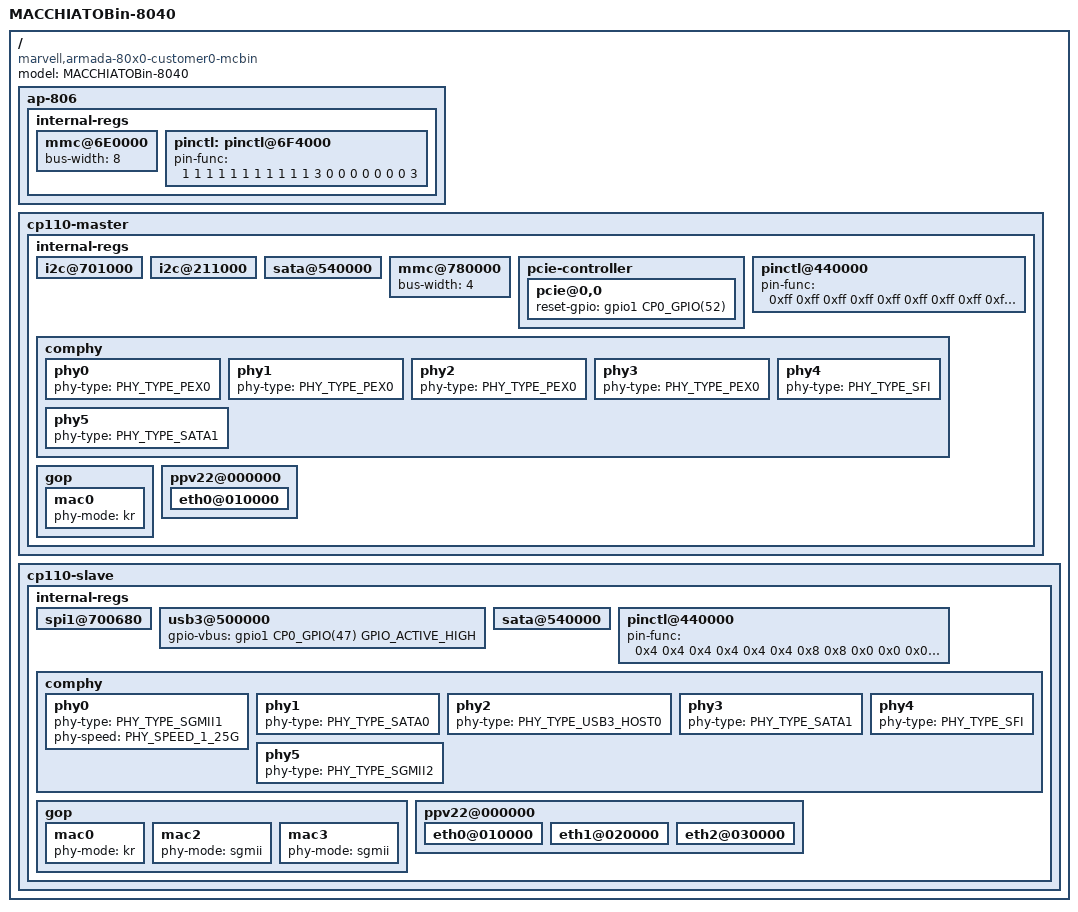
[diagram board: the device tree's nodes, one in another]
/*
 * ***************************************************************************
 * Copyright (C) 2016 Marvell International Ltd.
 * ***************************************************************************
 * This program is free software: you can redistribute it and/or modify it
 * under the terms of the GNU General Public License as published by the Free
 * Software Foundation, either version 2 of the License, or any later version.
 *
 * This program is distributed in the hope that it will be useful,
 * but WITHOUT ANY WARRANTY; without even the implied warranty of
 * MERCHANTABILITY or FITNESS FOR A PARTICULAR PURPOSE.  See the
 * GNU General Public License for more details.
 *
 * You should have received a copy of the GNU General Public License
 * along with this program.  If not, see <http://www.gnu.org/licenses/>.
 * ***************************************************************************
 */

/dts-v1/;

#include "armada-80x0.dtsi" /* include SoC device tree */

/ {
	model = "MACCHIATOBin-8040";
	compatible = "marvell,armada-80x0-customer0-mcbin", "marvell,armada-80x0";

	ap-806 {
		internal-regs {
			mmc@6E0000 {
				/* on-board eMMC */
				bus-width= <8>;
				status = "okay";
			};
			pinctl: pinctl@6F4000 {
					/* MPP Bus:
						eMMC [0..10]
						UART0 [11,19]
					*/
					  /* 0 1 2 3 4 5 6 7 8 9 */
				pin-func = < 1 1 1 1 1 1 1 1 1 1
					     1 3 0 0 0 0 0 0 0 3>;
			};
		};
	};
	cp110-master {
		internal-regs {
			i2c@701000 {
				status = "okay";
			};
			i2c@211000 {
				status = "okay";
			};
			sata@540000 {
				status = "okay";
			};
			mmc@780000 {
				/* uSD slot */
				bus-width= <4>;
				status = "okay";
			};
			pcie-controller {
				pcie@0,0 {
					reset-gpio = <&gpio1 CP0_GPIO(52) GPIO_ACTIVE_HIGH>;
					status = "okay";
				};
			};
			pinctl@440000 {
					/* MPP Bus:
					   [0-31] = 0xff: Keep default CP0_shared_pins:
						[11] CLKOUT_MPP_11 (out)
						[23] LINK_RD_IN_CP2CP (in)
						[25] CLKOUT_MPP_25 (out)
						[29] AVS_FB_IN_CP2CP (in)
					   [32,34] SMI
					   [33]    MSS power down
					   [35..38] CP0 I2C1 and I2C0
					   [39] MSS CKE Enable
					   [40,41] CP0 UART1 TX/RX
					   [42,43] XSMI (controls two 10G phys)
					   [47] USB VBUS EN
					   [48] FAN PWM
					   [49] 10G port 1 interrupt
					   [50] 10G port 0 interrupt
					   [51] 2.5G SFP TX fault
					   [52] PCIe reset out
					   [53] 2.5G SFP mode
					   [54] 2.5G SFP LOS
					   [55] Micro SD card detect
					   [56-61] Micro SD
					   [62] CP1 SFI SFP FAULT
					*/
					/*   0    1    2    3    4    5    6    7    8    9 */
				pin-func = < 0xff 0xff 0xff 0xff 0xff 0xff 0xff 0xff 0xff 0xff
					     0xff 0xff 0xff 0xff 0xff 0xff 0xff 0xff 0xff 0xff
					     0xff 0xff 0xff 0xff 0xff 0xff 0xff 0xff 0xff 0xff
					     0xff 0    7    0xa  7    2    2    2    2    0xa
					     7    7    8    8    0    0    0    0    0    0
					     0    0    9    0    0    0    0xe  0xe  0xe  0xe
					     0xe  0xe  0>;
			};

			comphy {
				/* CP0 Serdes Configuration:
					Lane 0: PCIe0 (x4)
					Lane 1: PCIe0 (x4)
					Lane 2: PCIe0 (x4)
					Lane 3: PCIe0 (x4)
					Lane 4: SFI (10G)
					Lane 5: SATA1
				*/
				phy0 {
					phy-type = <PHY_TYPE_PEX0>;
				};
				phy1 {
					phy-type = <PHY_TYPE_PEX0>;
				};
				phy2 {
					phy-type = <PHY_TYPE_PEX0>;
				};
				phy3 {
					phy-type = <PHY_TYPE_PEX0>;
				};
				phy4 {
					phy-type = <PHY_TYPE_SFI>;
				};
				phy5 {
					phy-type = <PHY_TYPE_SATA1>;
				};
			};
			gop {
				mac0 {
					phy-mode = "kr"; /* lane-4 */
				};
			};
			ppv22@000000 {
				eth0@010000 {
					status = "okay";
				};
			};
		};
	};
	cp110-slave {
		internal-regs {
			spi1@700680 {
				status = "okay";
			};
			usb3@500000 {
				status = "okay";
				gpio-vbus = <&gpio1 CP0_GPIO(47) GPIO_ACTIVE_HIGH>;
			};
			sata@540000 {
				status = "okay";
			};
			pinctl@440000 {
				/* MPP Bus:
				  [0-5] TDM
				  [6,7] CP1_UART 0
				  [8]   CP1 10G SFP LOS
				  [9]   CP1 10G PHY RESET
				  [10]  CP1 10G SFP TX Disable
				  [11]  CP1 10G SFP Mode
				  [12]  SPI1 CS1n
				  [13]  SPI1 MISO (TDM and SPI ROM shared)
				  [14]  SPI1 CS0n
				  [15]  SPI1 MOSI (TDM and SPI ROM shared)
				  [16]  SPI1 CLK (TDM and SPI ROM shared)
				  [24]  CP1 2.5G SFP TX Disable
				  [26]  CP0 10G SFP TX Fault
				  [27]  CP0 10G SFP Mode
				  [28]  CP0 10G SFP LOS
				  [29]  CP0 10G SFP TX Disable
				  [30]  USB Over current indication
				  [31]  10G Port 0 phy reset
				  [32-62] = 0xff: Keep default CP1_shared_pins:
				*/
					/*   0    1    2    3    4    5    6    7    8    9 */
				pin-func = < 0x4  0x4  0x4  0x4  0x4  0x4  0x8  0x8  0x0  0x0
					     0x0  0x0  0x3  0x3  0x3  0x3  0x3  0xff 0xff 0xff
					     0xff 0xff 0xff 0xff 0x0  0xff 0x0  0x0  0x0 0x0
					     0x0  0x0  0xff 0xff 0xff 0xff 0xff 0xff 0xff 0xff
					     0xff 0xff 0xff 0xff 0xff 0xff 0xff 0xff 0xff 0xff
					     0xff 0xff 0xff 0xff 0xff 0xff 0xff 0xff 0xff 0xff
					     0xff 0xff 0xff>;

			};
			comphy {
				/* CP1 Serdes Configuration:
					Lane 0: SGMII1
					Lane 1: SATA 0
					Lane 2: USB HOST 0
					Lane 3: SATA1
					Lane 4: SFI (10G)
					Lane 5: SGMII3
				*/
				phy0 {
					phy-type = <PHY_TYPE_SGMII1>;
					phy-speed = <PHY_SPEED_1_25G>;
				};
				phy1 {
					phy-type = <PHY_TYPE_SATA0>;
				};
				phy2 {
					phy-type = <PHY_TYPE_USB3_HOST0>;
				};
				phy3 {
					phy-type = <PHY_TYPE_SATA1>;
				};
				phy4 {
					phy-type = <PHY_TYPE_SFI>;
				};
				phy5 {
					phy-type = <PHY_TYPE_SGMII2>;
				};
			};
			gop {
				mac0 {
					phy-mode = "kr"; /* lane-4 */
				};
				mac2 {
					phy-mode = "sgmii"; /* lane-0 */
				};
				mac3 {
					phy-mode = "sgmii"; /* lane-5 */
				};
			};
			ppv22@000000 {
				status = "okay";
				eth0@010000 {
					status = "okay";
				};
				eth1@020000 {
					status = "okay";
				};
				eth2@030000 {
					status = "okay";
				};
			};
		};
	};
};
